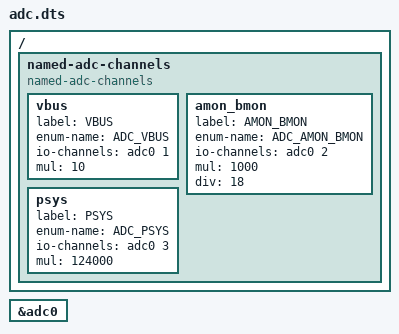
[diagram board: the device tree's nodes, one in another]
/* Copyright 2022 The Chromium OS Authors. All rights reserved.
 * Use of this source code is governed by a BSD-style license that can be
 * found in the LICENSE file.
 */

#include <dt-bindings/adc/adc.h>

/ {
	named-adc-channels {
		compatible = "named-adc-channels";

		vbus {
			label = "VBUS";
			enum-name = "ADC_VBUS";
			io-channels = <&adc0 1>;
			/* Measure VBUS through a 1/10 voltage divider */
			mul = <10>;
		};
		amon_bmon {
			label = "AMON_BMON";
			enum-name = "ADC_AMON_BMON";
			io-channels = <&adc0 2>;
			/*
			 * Adapter current output or battery charging/
			 * discharging current (uV) 18x amplification on
			 * charger side.
			 */
			mul = <1000>;
			div = <18>;
		};
		psys {
			label = "PSYS";
			enum-name = "ADC_PSYS";
			io-channels = <&adc0 3>;
			/*
			 * ISL9238 PSYS output is 1.44 uA/W over 5.6K resistor,
			 * to read 0.8V @ 99 W, i.e. 124000 uW/mV.
			 */
			mul = <124000>;
		};
	};
};

&adc0 {
	status = "okay";
};
